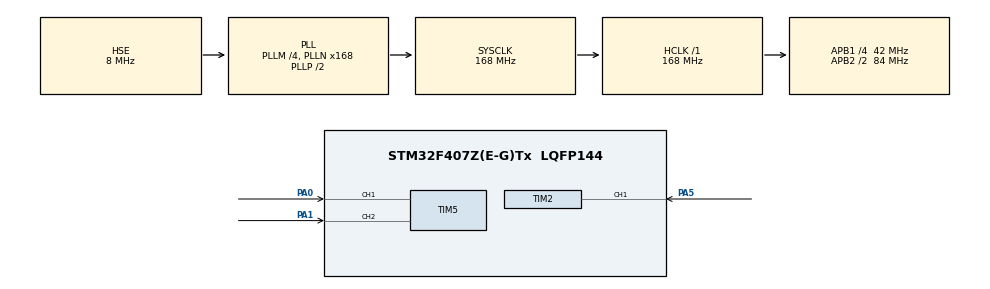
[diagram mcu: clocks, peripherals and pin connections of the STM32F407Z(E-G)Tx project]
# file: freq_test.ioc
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Mcu.Family=STM32F4
RCC.PLLSourceVirtual=RCC_PLLSOURCE_HSE
Dma.TIM2_CH1.0.MemInc=DMA_MINC_ENABLE
VP_TIM5_VS_ClockSourceINT.Mode=Internal
PH0-OSC_IN.Signal=RCC_OSC_IN
RCC.CortexFreq_Value=168000000
TIM2.Channel-Input_Capture1_from_TI1=TIM_CHANNEL_1
VP_TIM2_VS_ControllerModeReset.Mode=Reset Mode
SH.S_TIM5_CH2.0=TIM5_CH2,TriggerSource_TI2FP2
Dma.TIM2_CH1.0.Instance=DMA1_Stream5
RCC.APB1CLKDivider=RCC_HCLK_DIV4
RCC.SYSCLKSource=RCC_SYSCLKSOURCE_PLLCLK
ProjectManager.StackSize=0x400
PA0-WKUP.Signal=S_TIM5_CH1
ProjectManager.TargetToolchain=STM32CubeIDE
RCC.HCLKFreq_Value=168000000
RCC.APB2TimFreq_Value=168000000
TIM3.Period=8399
TIM5.TIM_MasterSlaveMode=TIM_MASTERSLAVEMODE_ENABLE
RCC.LSE_VALUE=32768
PA1.Signal=S_TIM5_CH2
RCC.AHBFreq_Value=168000000
PH0-OSC_IN.Mode=HSE-External-Oscillator
PA5.Signal=S_TIM2_CH1_ETR
RCC.HSE_VALUE=8000000
board=custom
RCC.VCOOutputFreq_Value=336000000
NVIC.TIM3_IRQn=true\:0\:0\:false\:false\:true\:true\:true
RCC.APB2Freq_Value=84000000
VP_TIM5_VS_ControllerModeReset.Mode=Reset Mode
Dma.TIM2_CH1.0.Priority=DMA_PRIORITY_LOW
VP_TIM2_VS_ClockSourceINT.Mode=Internal
TIM3.Prescaler=9999
PH1-OSC_OUT.Signal=RCC_OSC_OUT
TIM5.Channel-Input_Capture1_from_TI1=TIM_CHANNEL_1
Mcu.Name=STM32F407Z(E-G)Tx
PH1-OSC_OUT.Mode=HSE-External-Oscillator
RCC.48MHZClocksFreq_Value=84000000
RCC.SYSCLKFreq_VALUE=168000000
Mcu.Package=LQFP144
Dma.TIM2_CH1.0.Mode=DMA_CIRCULAR
Dma.TIM2_CH1.0.FIFOMode=DMA_FIFOMODE_DISABLE
SH.S_TIM2_CH1_ETR.1=TIM2_CH1,Input_Capture1_from_TI1
Dma.TIM2_CH1.0.MemDataAlignment=DMA_MDATAALIGN_WORD
SH.S_TIM2_CH1_ETR.0=TIM2_CH1,TriggerSource_TI1FP1
ProjectManager.HeapSize=0x200
Dma.TIM2_CH1.0.PeriphDataAlignment=DMA_PDATAALIGN_WORD
RCC.HSI_VALUE=16000000
NVIC.PriorityGroup=NVIC_PRIORITYGROUP_4
RCC.APB2CLKDivider=RCC_HCLK_DIV2
RCC.PLLM=4
RCC.PLLN=168
TIM2.TIM_MasterSlaveMode=TIM_MASTERSLAVEMODE_ENABLE
RCC.APB1TimFreq_Value=84000000
SH.S_TIM5_CH1.0=TIM5_CH1,Input_Capture1_from_TI1
RCC.APB1Freq_Value=42000000
Dma.Request0=TIM2_CH1
Dma.TIM2_CH1.0.Direction=DMA_PERIPH_TO_MEMORY
Dma.TIM2_CH1.0.PeriphInc=DMA_PINC_DISABLE
VP_TIM3_VS_ClockSourceINT.Mode=Internal

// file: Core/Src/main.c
/* USER CODE BEGIN Header */
/**
  ******************************************************************************
  * @file           : main.c
  * @brief          : Main program body
  ******************************************************************************
  * @attention
  *
  * <h2><center>&copy; Copyright (c) 2021 STMicroelectronics.
  * All rights reserved.</center></h2>
  *
  * This software component is licensed by ST under BSD 3-Clause license,
  * the "License"; You may not use this file except in compliance with the
  * License. You may obtain a copy of the License at:
  *                        opensource.org/licenses/BSD-3-Clause
  *
  ******************************************************************************
  */
/* USER CODE END Header */
#include "main.h"

/* USER CODE BEGIN PM */
uint32_t ch1_get;
uint32_t aaa;
/* USER CODE END PM */

TIM_HandleTypeDef htim2;
TIM_HandleTypeDef htim3;
TIM_HandleTypeDef htim5;
DMA_HandleTypeDef hdma_tim2_ch1;

void SystemClock_Config(void);
static void MX_GPIO_Init(void);
static void MX_DMA_Init(void);
static void MX_TIM2_Init(void);
static void MX_TIM3_Init(void);
static void MX_TIM5_Init(void);

int main(void)
{

  /* MCU Configuration--------------------------------------------------------*/

  /* Reset of all peripherals, Initializes the Flash interface and the Systick. */
  HAL_Init();

  /* Configure the system clock */
  SystemClock_Config();

  /* Initialize all configured peripherals */
  MX_GPIO_Init();
  MX_DMA_Init();
  MX_TIM2_Init();
  MX_TIM3_Init();
  MX_TIM5_Init();
  /* USER CODE BEGIN 2 */
  HAL_TIM_Base_Start(&htim2);
  HAL_TIM_IC_Start_DMA(&htim2,TIM_CHANNEL_1,&ch1_get,1);
  htim2.State = HAL_TIM_STATE_READY;
  HAL_TIM_Base_Start_IT(&htim3);
  /* USER CODE END 2 */

  /* Infinite loop */
  while (1)
  {

  }
}

void SystemClock_Config(void)
{
  RCC_OscInitTypeDef RCC_OscInitStruct = {0};
  RCC_ClkInitTypeDef RCC_ClkInitStruct = {0};

  /** Configure the main internal regulator output voltage
  */
  __HAL_RCC_PWR_CLK_ENABLE();
  __HAL_PWR_VOLTAGESCALING_CONFIG(PWR_REGULATOR_VOLTAGE_SCALE1);
  /** Initializes the RCC Oscillators according to the specified parameters
  * in the RCC_OscInitTypeDef structure.
  */
  RCC_OscInitStruct.OscillatorType = RCC_OSCILLATORTYPE_HSE;
  RCC_OscInitStruct.HSEState = RCC_HSE_ON;
  RCC_OscInitStruct.PLL.PLLState = RCC_PLL_ON;
  RCC_OscInitStruct.PLL.PLLSource = RCC_PLLSOURCE_HSE;
  RCC_OscInitStruct.PLL.PLLM = 4;
  RCC_OscInitStruct.PLL.PLLN = 168;
  RCC_OscInitStruct.PLL.PLLP = RCC_PLLP_DIV2;
  RCC_OscInitStruct.PLL.PLLQ = 4;
  if (HAL_RCC_OscConfig(&RCC_OscInitStruct) != HAL_OK)
  {
    Error_Handler();
  }
  /** Initializes the CPU, AHB and APB buses clocks
  */
  RCC_ClkInitStruct.ClockType = RCC_CLOCKTYPE_HCLK|RCC_CLOCKTYPE_SYSCLK
                              |RCC_CLOCKTYPE_PCLK1|RCC_CLOCKTYPE_PCLK2;
  RCC_ClkInitStruct.SYSCLKSource = RCC_SYSCLKSOURCE_PLLCLK;
  RCC_ClkInitStruct.AHBCLKDivider = RCC_SYSCLK_DIV1;
  RCC_ClkInitStruct.APB1CLKDivider = RCC_HCLK_DIV4;
  RCC_ClkInitStruct.APB2CLKDivider = RCC_HCLK_DIV2;

  if (HAL_RCC_ClockConfig(&RCC_ClkInitStruct, FLASH_LATENCY_5) != HAL_OK)
  {
    Error_Handler();
  }
}

static void MX_TIM2_Init(void)
{

  TIM_ClockConfigTypeDef sClockSourceConfig = {0};
  TIM_SlaveConfigTypeDef sSlaveConfig = {0};
  TIM_MasterConfigTypeDef sMasterConfig = {0};
  TIM_IC_InitTypeDef sConfigIC = {0};

  htim2.Instance = TIM2;
  htim2.Init.Prescaler = 0;
  htim2.Init.CounterMode = TIM_COUNTERMODE_UP;
  htim2.Init.Period = 4294967295;
  htim2.Init.ClockDivision = TIM_CLOCKDIVISION_DIV1;
  htim2.Init.AutoReloadPreload = TIM_AUTORELOAD_PRELOAD_DISABLE;
  if (HAL_TIM_Base_Init(&htim2) != HAL_OK)
  {
    Error_Handler();
  }
  sClockSourceConfig.ClockSource = TIM_CLOCKSOURCE_INTERNAL;
  if (HAL_TIM_ConfigClockSource(&htim2, &sClockSourceConfig) != HAL_OK)
  {
    Error_Handler();
  }
  if (HAL_TIM_IC_Init(&htim2) != HAL_OK)
  {
    Error_Handler();
  }
  sSlaveConfig.SlaveMode = TIM_SLAVEMODE_RESET;
  sSlaveConfig.InputTrigger = TIM_TS_TI1FP1;
  sSlaveConfig.TriggerPolarity = TIM_INPUTCHANNELPOLARITY_RISING;
  sSlaveConfig.TriggerFilter = 0;
  if (HAL_TIM_SlaveConfigSynchro(&htim2, &sSlaveConfig) != HAL_OK)
  {
    Error_Handler();
  }
  sMasterConfig.MasterOutputTrigger = TIM_TRGO_RESET;
  sMasterConfig.MasterSlaveMode = TIM_MASTERSLAVEMODE_ENABLE;
  if (HAL_TIMEx_MasterConfigSynchronization(&htim2, &sMasterConfig) != HAL_OK)
  {
    Error_Handler();
  }
  sConfigIC.ICPolarity = TIM_INPUTCHANNELPOLARITY_RISING;
  sConfigIC.ICSelection = TIM_ICSELECTION_DIRECTTI;
  sConfigIC.ICPrescaler = TIM_ICPSC_DIV1;
  sConfigIC.ICFilter = 0;
  if (HAL_TIM_IC_ConfigChannel(&htim2, &sConfigIC, TIM_CHANNEL_1) != HAL_OK)
  {
    Error_Handler();
  }

}

static void MX_TIM3_Init(void)
{

  TIM_ClockConfigTypeDef sClockSourceConfig = {0};
  TIM_MasterConfigTypeDef sMasterConfig = {0};

  htim3.Instance = TIM3;
  htim3.Init.Prescaler = 9999;
  htim3.Init.CounterMode = TIM_COUNTERMODE_UP;
  htim3.Init.Period = 8399;
  htim3.Init.ClockDivision = TIM_CLOCKDIVISION_DIV1;
  htim3.Init.AutoReloadPreload = TIM_AUTORELOAD_PRELOAD_DISABLE;
  if (HAL_TIM_Base_Init(&htim3) != HAL_OK)
  {
    Error_Handler();
  }
  sClockSourceConfig.ClockSource = TIM_CLOCKSOURCE_INTERNAL;
  if (HAL_TIM_ConfigClockSource(&htim3, &sClockSourceConfig) != HAL_OK)
  {
    Error_Handler();
  }
  sMasterConfig.MasterOutputTrigger = TIM_TRGO_RESET;
  sMasterConfig.MasterSlaveMode = TIM_MASTERSLAVEMODE_DISABLE;
  if (HAL_TIMEx_MasterConfigSynchronization(&htim3, &sMasterConfig) != HAL_OK)
  {
    Error_Handler();
  }

}

static void MX_TIM5_Init(void)
{

  TIM_ClockConfigTypeDef sClockSourceConfig = {0};
  TIM_SlaveConfigTypeDef sSlaveConfig = {0};
  TIM_MasterConfigTypeDef sMasterConfig = {0};
  TIM_IC_InitTypeDef sConfigIC = {0};

  htim5.Instance = TIM5;
  htim5.Init.Prescaler = 0;
  htim5.Init.CounterMode = TIM_COUNTERMODE_UP;
  htim5.Init.Period = 4294967295;
  htim5.Init.ClockDivision = TIM_CLOCKDIVISION_DIV1;
  htim5.Init.AutoReloadPreload = TIM_AUTORELOAD_PRELOAD_DISABLE;
  if (HAL_TIM_Base_Init(&htim5) != HAL_OK)
  {
    Error_Handler();
  }
  sClockSourceConfig.ClockSource = TIM_CLOCKSOURCE_INTERNAL;
  if (HAL_TIM_ConfigClockSource(&htim5, &sClockSourceConfig) != HAL_OK)
  {
    Error_Handler();
  }
  if (HAL_TIM_IC_Init(&htim5) != HAL_OK)
  {
    Error_Handler();
  }
  sSlaveConfig.SlaveMode = TIM_SLAVEMODE_RESET;
  sSlaveConfig.InputTrigger = TIM_TS_TI2FP2;
  sSlaveConfig.TriggerPolarity = TIM_TRIGGERPOLARITY_RISING;
  sSlaveConfig.TriggerFilter = 0;
  if (HAL_TIM_SlaveConfigSynchro(&htim5, &sSlaveConfig) != HAL_OK)
  {
    Error_Handler();
  }
  sMasterConfig.MasterOutputTrigger = TIM_TRGO_RESET;
  sMasterConfig.MasterSlaveMode = TIM_MASTERSLAVEMODE_ENABLE;
  if (HAL_TIMEx_MasterConfigSynchronization(&htim5, &sMasterConfig) != HAL_OK)
  {
    Error_Handler();
  }
  sConfigIC.ICPolarity = TIM_INPUTCHANNELPOLARITY_RISING;
  sConfigIC.ICSelection = TIM_ICSELECTION_DIRECTTI;
  sConfigIC.ICPrescaler = TIM_ICPSC_DIV1;
  sConfigIC.ICFilter = 0;
  if (HAL_TIM_IC_ConfigChannel(&htim5, &sConfigIC, TIM_CHANNEL_1) != HAL_OK)
  {
    Error_Handler();
  }

}

static void MX_DMA_Init(void)
{

  /* DMA controller clock enable */
  __HAL_RCC_DMA1_CLK_ENABLE();

}

static void MX_GPIO_Init(void)
{

  /* GPIO Ports Clock Enable */
  __HAL_RCC_GPIOH_CLK_ENABLE();
  __HAL_RCC_GPIOA_CLK_ENABLE();

}

void Error_Handler(void)
{
  __disable_irq();
  while (1)
  {
  }
}

/************************ (C) COPYRIGHT STMicroelectronics *****END OF FILE****/
